# MB9AFA4xM register map
File version: 1.7
CPU: 
Registers are 8-bit, read-write, reset 0x0 unless marked. A register's access mark holds for its fields unless they carry their own. Offsets are from the block's base; [hi:lo] are bit positions; {n}, {i} and the like mark numbered series.

## WC — Watch Counter
Base 0x4003A000
0x00 WCRD ro — Watch Counter Read Register
  [5:0] CTR — counter value
0x01 WCRL — Watch Counter Reload Register
  [5:0] RLC — reload value
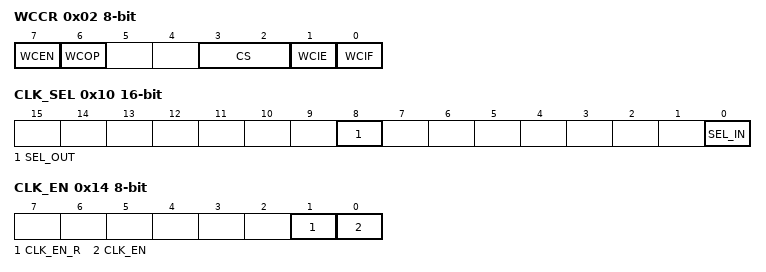
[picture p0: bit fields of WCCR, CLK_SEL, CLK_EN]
0x02 WCCR — Watch Counter Control Register
  [7] WCEN — Watch counter operation enable bit
  [6] WCOP ro — Watch counter operating state flag
  [3:2] CS — Count clock select bits
  [1] WCIE — Interrupt request enable bit
  [0] WCIF — Interrupt request flag bit
0x10 CLK_SEL 16-bit — Clock Selection Register
  [8] SEL_OUT — Output clock selection bit
  [0] SEL_IN — Input clock selection bit
0x14 CLK_EN — Division Clock Enable Register
  [1] CLK_EN_R — Division clock enable read bit
  [0] CLK_EN — Division clock enable bit

## EXTI — External Interrupt and NMI Control
Base 0x40030000
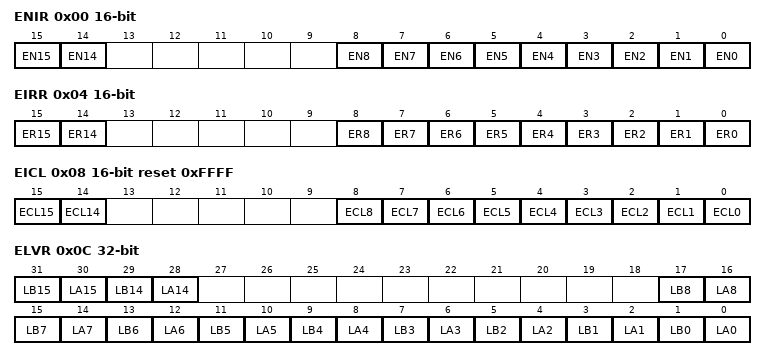
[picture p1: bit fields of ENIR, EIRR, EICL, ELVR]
0x00 ENIR 16-bit — Enable Interrupt Request Register
  [15] EN15 — Bit15 of ENIR
  [14] EN14 — Bit14 of ENIR
  [n] EN{n} (n=0..8) — Bit{n} of ENIR
0x04 EIRR 16-bit ro reset not defined — External Interrupt Request Register
  [15] ER15 — Bit15 of EIRR
  [14] ER14 — Bit14 of EIRR
  [n] ER{n} (n=0..8) — Bit{n} of EIRR
0x08 EICL 16-bit reset 0xFFFF — External Interrupt Clear Register
  [15] ECL15 — Bit15 of EICL
  [14] ECL14 — Bit14 of EICL
  [n] ECL{n} (n=0..8) — Bit{n} of EICL
0x0C ELVR 32-bit — External Interrupt Level Register
  [31] LB15 — Bit31 of ELVR
  [30] LA15 — Bit30 of ELVR
  [29] LB14 — Bit29 of ELVR
  [28] LA14 — Bit28 of ELVR
  [2n+1] LB{n} (n=0..8) — Bit{2n+1} of ELVR
  [2n] LA{n} (n=0..8) — Bit{2n} of ELVR
0x14 NMIRR ro — Non Maskable Interrupt Request Register
  [0] NR — NMI interrupt request detection bit
0x18 NMICL reset 0x1 — Non Maskable Interrupt Clear Register
  [0] NCL — NMI interrupt cause clear bit

## LCDC — LCD Controller
Base 0x40032000
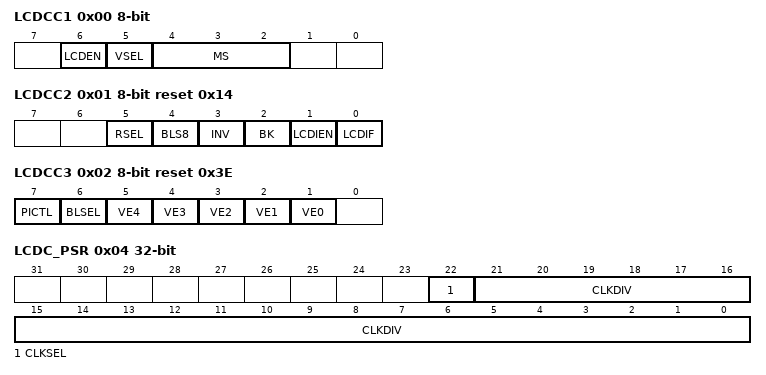
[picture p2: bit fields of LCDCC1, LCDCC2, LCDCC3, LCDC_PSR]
0x00 LCDCC1 — LCDC Control Register 1
  [6] LCDEN — Timer mode operation enable bit
  [5] VSEL — LCD drive power control bit
  [4:2] MS — LCD controller display mode selection bits
0x01 LCDCC2 reset 0x14 — LCDC Control Register 2
  [5] RSEL — Divider resistor value selection bit
  [4] BLS8 — 8 COM mode bias selection bit
  [3] INV — Reverse display control bit
  [2] BK — Blank display control bit
  [1] LCDIEN — Interrupt enable bit
  [0] LCDIF — Interrupt request detection bit
0x02 LCDCC3 reset 0x3E — LCDC Control Register 3
  [7] PICTL — I/O port input control bit
  [6] BLSEL — Blink interval selection bit
  [n+1] VE{n} (n=0..4) — VV{n} selection bit
0x04 LCDC_PSR 32-bit — LCDC Clock Prescaler Register
  [22] CLKSEL — Source clock selection bit
  [21:0] CLKDIV — LCDC clock division ratio setting bit
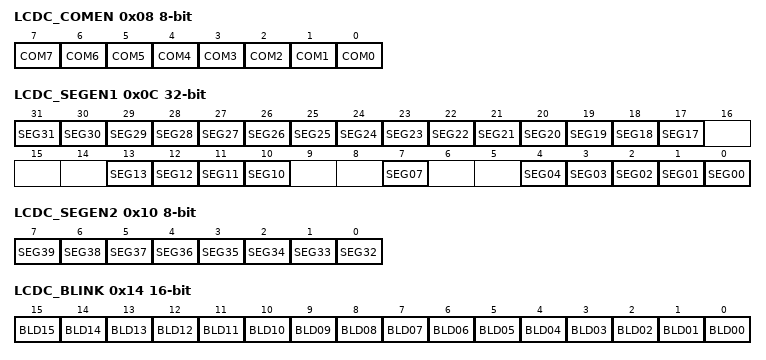
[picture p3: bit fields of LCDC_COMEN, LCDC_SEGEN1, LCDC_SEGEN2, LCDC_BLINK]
0x08 LCDC_COMEN — LCDC COM Output Enable Register
  [n] COM{n} (n=4..7) — Dual purpose COM/SEG port control bits
  [n] COM{n} (n=0..3) — Dual purpose COM port control bit
0x0C LCDC_SEGEN1 32-bit — LCDC SEG Output Enable Register 1
  [n] SEG{n} (n=17..31) — Segment {n}
  [n] SEG{n} (n=10..13) — Segment {n}
  [7] SEG07 — Segment 7
  [n] SEG{n:02} (n=0..4) — Segment {n}
0x10 LCDC_SEGEN2 — LCDC SEG Output Enable Register 2
  [n-32] SEG{n} (n=32..39) — Segment {n}
0x14 LCDC_BLINK 16-bit — LCDC Blink Setting Register
  [n] BLD{n:02} (n=0..15) — Blink operation control bit {n}
{0x1C+i} LCDRAM{i:02} (i=0..39) — Display Data Memory Register {i:02}
  [7:0] LCDRAM — Display Data {i:02}

## HDMICEC0 — HDMI-CEC ch.0
Base 0x40034000
Same registers: HDMICEC1 0x40034100
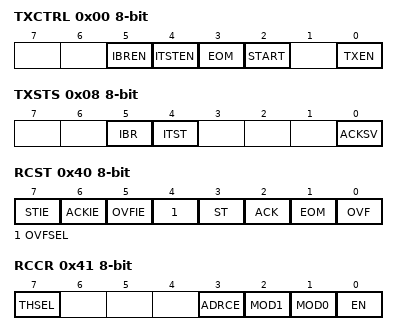
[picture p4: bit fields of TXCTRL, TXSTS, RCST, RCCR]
0x00 TXCTRL — Transmission Control Register
  [5] IBREN — Bus error detection interrupt enable bit
  [4] ITSTEN — transmission status interrupt enable bit
  [3] EOM — EOM setting bit
  [2] START — START setting bit
  [0] TXEN — Transmission operation enable bit
0x04 TXDATA — Transmission Data Register
  [7:0] TXDATA — Transmission Data
0x08 TXSTS — Transmission Status Register
  [5] IBR — Bus error detection interrupt request bit
  [4] ITST — Transmission status interrupt request bit
  [0] ACKSV — ACK cycle value bit
0x0C SFREE — Signal Free Time Setting Register
  [3:0] SFREE — Signal free time setting bits
0x40 RCST — Reception Interrupt Control Register
  [7] STIE — Start bit interrupt enable bit
  [6] ACKIE — ACK interrupt enable bit
  [5] OVFIE — Counter overflow interrupt enable bit
  [4] OVFSEL — Counter overflow detection condition setting bit
  [3] ST — Start bit detection bit
  [2] ACK — ACK: ACK detection bit
  [1] EOM — EOM detection bit
  [0] OVF — Counter overflow detection bit
0x41 RCCR — Reception Control Register
  [7] THSEL — Threshold selection bit
  [3] ADRCE — Address comparison enable bit
  [2] MOD1 — Operation mode setting bits
  [1] MOD0 — Operation mode setting bits
  [0] EN — Operation enable bit
0x44 RCDAHW — "H" Width Setting Register A
  [7:0] RCDAHW — "H" Width Setting A
0x45 RCSHW — Start Bit "H" Width Setting Register
  [7:0] RCSHW — Start Bit "H" Width Setting
0x49 RCDBHW — "H" Width Setting Register B
  [7:0] RCDBHW — "H" Width Setting B
0x4C RCADR2 — Device Address Setting Register 2
  [4:0] RCADR2 — Device Address 2
0x4D RCADR1 — Device Address Setting Register 1
  [4:0] RCADR1 — Device Address 1
0x50 RCDTHL ro — Data Save Register (High-Low)
0x51 RCDTHH ro — Data Save Register (High-High)
0x54 RCDTLL ro — Data Save Register (Low-Low)
0x55 RCDTLH ro — Data Save Register (Low-High)
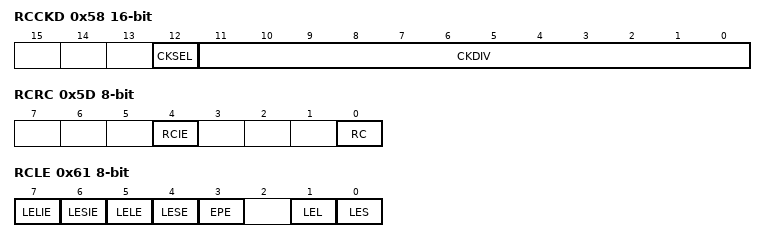
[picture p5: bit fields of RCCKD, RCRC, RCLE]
0x58 RCCKD 16-bit — Clock Division Setting Register
  [12] CKSEL — Operating clock selection bit
  [11:0] CKDIV — Operating clock division setting bits
0x5C RCRHW — Repeat Code "H" Width Setting Register
  [7:0] RCRHW — "Repeat code "H" width setting bits"
0x5D RCRC — Repeat Code Interrupt Control Register
  [4] RCIE — Repeat Code Interrupt enable bit
  [0] RC — Repeat code detection flag bit
0x61 RCLE — Data Bit Width Violation Control Register
  [7] LELIE — Maximum data bit width violation interrupt enable bit
  [6] LESIE — Minimum data bit width violation interrupt enable bit
  [5] LELE — Maximum data bit width violation detection enable bit
  [4] LESE — Minimum data bit width violation detection enable bit
  [3] EPE — Error pulse output enable bit
  [1] LEL — Maximum data bit width violation detection flag bit
  [0] LES — Minimum data bit width violation detection flag bit
0x64 RCLESW — Minimum Data Bit Width Setting Register
  [7:0] RCLESW — Minimum data bit width setting bits
0x65 RCLELW — Maximum Data Bit Width Setting Register
  [7:0] RCLELW — Maximum data bit width setting bits
